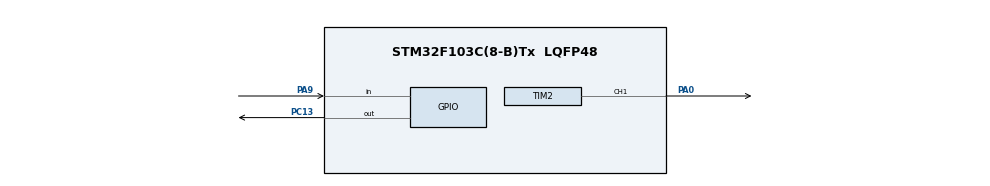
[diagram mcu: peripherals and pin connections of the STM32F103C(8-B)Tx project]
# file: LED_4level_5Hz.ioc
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Mcu.Family=STM32F1
Mcu.Name=STM32F103C(8-B)Tx
Mcu.Package=LQFP48
NVIC.PriorityGroup=NVIC_PRIORITYGROUP_4
NVIC.TIM1_UP_IRQn=true\:0\:0\:false\:false\:true\:true\:true\:true
PA0-WKUP.Signal=S_TIM2_CH1_ETR
PA13.Mode=Serial_Wire
PA13.Signal=SYS_JTMS-SWDIO
PA14.Mode=Serial_Wire
PA14.Signal=SYS_JTCK-SWCLK
PA9.GPIO_PuPd=GPIO_PULLUP
PA9.Signal=GPIO_Input
PC13-TAMPER-RTC.GPIO_ModeDefaultOutputPP=GPIO_MODE_OUTPUT_OD
PC13-TAMPER-RTC.GPIO_PuPd=GPIO_NOPULL
PC13-TAMPER-RTC.PinState=GPIO_PIN_SET
PC13-TAMPER-RTC.Signal=GPIO_Output
ProjectManager.HeapSize=0x200
ProjectManager.StackSize=0x400
ProjectManager.TargetToolchain=MDK-ARM V5.32
RCC.APB1Freq_Value=8000000
RCC.APB2Freq_Value=8000000
SH.S_TIM2_CH1_ETR.0=TIM2_CH1,PWM Generation1 CH1
TIM1.Period=99
TIM1.Prescaler=799
TIM2.Channel-PWM\ Generation1\ CH1=TIM_CHANNEL_1
TIM2.Period=999
TIM2.Prescaler=7
VP_TIM1_VS_ClockSourceINT.Mode=Internal
VP_TIM2_VS_ClockSourceINT.Mode=Internal
board=custom

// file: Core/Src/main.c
/* USER CODE BEGIN Header */
/**
  ******************************************************************************
  * @file           : main.c
  * @brief          : Main program body
  ******************************************************************************
  * @attention
  *
  * Copyright (c) 2026 STMicroelectronics.
  * All rights reserved.
  *
  * This software is licensed under terms that can be found in the LICENSE file
  * in the root directory of this software component.
  * If no LICENSE file comes with this software, it is provided AS-IS.
  *
  ******************************************************************************
  */
/* USER CODE END Header */
#include "main.h"

TIM_HandleTypeDef htim1;
TIM_HandleTypeDef htim2;

/* USER CODE BEGIN PV */
volatile uint8_t LED_long_flag = 0;//1表示长按进入呼吸灯效果
volatile uint8_t LED_short_flag = 0;//1表示短按，4种亮度循环变化
uint8_t key_state_per = 1 ;//上一次按键状态
uint8_t key_state_cur =1;//当前按键状态
uint16_t LED_ccr = 0;//LED的ccr值
int8_t LED_step = 1;//长按呼吸灯的单次改变值
uint8_t tick = 0;//每1ms一次
uint8_t mode = 1;//1为短按模式，2为长按模式
uint8_t level = 0;//亮度等级1到4
volatile uint8_t breath_flag = 0;//1为呼吸灯进行的标志
/* USER CODE END PV */

void SystemClock_Config(void);
static void MX_GPIO_Init(void);
static void MX_TIM1_Init(void);
static void MX_TIM2_Init(void);

int main(void)
{

  /* MCU Configuration--------------------------------------------------------*/

  /* Reset of all peripherals, Initializes the Flash interface and the Systick. */
  HAL_Init();

  /* Configure the system clock */
  SystemClock_Config();

  /* Initialize all configured peripherals */
  MX_GPIO_Init();
  MX_TIM1_Init();
  MX_TIM2_Init();
  /* USER CODE BEGIN 2 */
  HAL_TIM_Base_Start_IT(&htim1);//启动定时器1，并开启中断
  HAL_TIM_PWM_Start(&htim2, TIM_CHANNEL_1);//定时器2输出PWM波
  /* USER CODE END 2 */

  /* Infinite loop */
  /* USER CODE BEGIN WHILE */
  while (1)
  {
    if(LED_long_flag == 1)//出现长按标记
    {
      if(mode == 1)
      {
        mode = 2;
      }
      else if(mode == 2)
      {
        mode = 1;
      }
      LED_long_flag = 0;
    }
    if(LED_short_flag == 1 && mode == 1)//短按标志出现
    {
      if(level < 4)
      {
        level++;
      }
      else if(level >= 4)
      {
        level = 1;
      }
      LED_ccr = 250 * level;
      __HAL_TIM_SET_COMPARE(&htim2, TIM_CHANNEL_1, LED_ccr);
      LED_short_flag = 0;
    }
    if(mode == 2 && breath_flag == 1)
    {
      breath_flag = 0;
      LED_ccr += LED_step;
      if(LED_ccr >= 1000)
      {
        LED_step = -LED_step;
      }
      if(LED_ccr <= 0)
      {
        LED_step = -LED_step;
      }
      __HAL_TIM_SET_COMPARE(&htim2, TIM_CHANNEL_1, LED_ccr);

    }
    /* USER CODE END WHILE */

  }
}

void SystemClock_Config(void)
{
  RCC_OscInitTypeDef RCC_OscInitStruct = {0};
  RCC_ClkInitTypeDef RCC_ClkInitStruct = {0};

  /** Initializes the RCC Oscillators according to the specified parameters
  * in the RCC_OscInitTypeDef structure.
  */
  RCC_OscInitStruct.OscillatorType = RCC_OSCILLATORTYPE_HSI;
  RCC_OscInitStruct.HSIState = RCC_HSI_ON;
  RCC_OscInitStruct.HSICalibrationValue = RCC_HSICALIBRATION_DEFAULT;
  RCC_OscInitStruct.PLL.PLLState = RCC_PLL_NONE;
  if (HAL_RCC_OscConfig(&RCC_OscInitStruct) != HAL_OK)
  {
    Error_Handler();
  }

  /** Initializes the CPU, AHB and APB buses clocks
  */
  RCC_ClkInitStruct.ClockType = RCC_CLOCKTYPE_HCLK|RCC_CLOCKTYPE_SYSCLK
                              |RCC_CLOCKTYPE_PCLK1|RCC_CLOCKTYPE_PCLK2;
  RCC_ClkInitStruct.SYSCLKSource = RCC_SYSCLKSOURCE_HSI;
  RCC_ClkInitStruct.AHBCLKDivider = RCC_SYSCLK_DIV1;
  RCC_ClkInitStruct.APB1CLKDivider = RCC_HCLK_DIV1;
  RCC_ClkInitStruct.APB2CLKDivider = RCC_HCLK_DIV1;

  if (HAL_RCC_ClockConfig(&RCC_ClkInitStruct, FLASH_LATENCY_0) != HAL_OK)
  {
    Error_Handler();
  }
}

static void MX_TIM1_Init(void)
{

  TIM_ClockConfigTypeDef sClockSourceConfig = {0};
  TIM_MasterConfigTypeDef sMasterConfig = {0};

  htim1.Instance = TIM1;
  htim1.Init.Prescaler = 799;
  htim1.Init.CounterMode = TIM_COUNTERMODE_UP;
  htim1.Init.Period = 99;
  htim1.Init.ClockDivision = TIM_CLOCKDIVISION_DIV1;
  htim1.Init.RepetitionCounter = 0;
  htim1.Init.AutoReloadPreload = TIM_AUTORELOAD_PRELOAD_DISABLE;
  if (HAL_TIM_Base_Init(&htim1) != HAL_OK)
  {
    Error_Handler();
  }
  sClockSourceConfig.ClockSource = TIM_CLOCKSOURCE_INTERNAL;
  if (HAL_TIM_ConfigClockSource(&htim1, &sClockSourceConfig) != HAL_OK)
  {
    Error_Handler();
  }
  sMasterConfig.MasterOutputTrigger = TIM_TRGO_RESET;
  sMasterConfig.MasterSlaveMode = TIM_MASTERSLAVEMODE_DISABLE;
  if (HAL_TIMEx_MasterConfigSynchronization(&htim1, &sMasterConfig) != HAL_OK)
  {
    Error_Handler();
  }

}

static void MX_TIM2_Init(void)
{

  TIM_ClockConfigTypeDef sClockSourceConfig = {0};
  TIM_MasterConfigTypeDef sMasterConfig = {0};
  TIM_OC_InitTypeDef sConfigOC = {0};

  htim2.Instance = TIM2;
  htim2.Init.Prescaler = 7;
  htim2.Init.CounterMode = TIM_COUNTERMODE_UP;
  htim2.Init.Period = 999;
  htim2.Init.ClockDivision = TIM_CLOCKDIVISION_DIV1;
  htim2.Init.AutoReloadPreload = TIM_AUTORELOAD_PRELOAD_DISABLE;
  if (HAL_TIM_Base_Init(&htim2) != HAL_OK)
  {
    Error_Handler();
  }
  sClockSourceConfig.ClockSource = TIM_CLOCKSOURCE_INTERNAL;
  if (HAL_TIM_ConfigClockSource(&htim2, &sClockSourceConfig) != HAL_OK)
  {
    Error_Handler();
  }
  if (HAL_TIM_PWM_Init(&htim2) != HAL_OK)
  {
    Error_Handler();
  }
  sMasterConfig.MasterOutputTrigger = TIM_TRGO_RESET;
  sMasterConfig.MasterSlaveMode = TIM_MASTERSLAVEMODE_DISABLE;
  if (HAL_TIMEx_MasterConfigSynchronization(&htim2, &sMasterConfig) != HAL_OK)
  {
    Error_Handler();
  }
  sConfigOC.OCMode = TIM_OCMODE_PWM1;
  sConfigOC.Pulse = 0;
  sConfigOC.OCPolarity = TIM_OCPOLARITY_HIGH;
  sConfigOC.OCFastMode = TIM_OCFAST_DISABLE;
  if (HAL_TIM_PWM_ConfigChannel(&htim2, &sConfigOC, TIM_CHANNEL_1) != HAL_OK)
  {
    Error_Handler();
  }
  HAL_TIM_MspPostInit(&htim2);

}

static void MX_GPIO_Init(void)
{
  GPIO_InitTypeDef GPIO_InitStruct = {0};

  /* GPIO Ports Clock Enable */
  __HAL_RCC_GPIOC_CLK_ENABLE();
  __HAL_RCC_GPIOA_CLK_ENABLE();

  /*Configure GPIO pin Output Level */
  HAL_GPIO_WritePin(GPIOC, GPIO_PIN_13, GPIO_PIN_SET);

  /*Configure GPIO pin : PC13 */
  GPIO_InitStruct.Pin = GPIO_PIN_13;
  GPIO_InitStruct.Mode = GPIO_MODE_OUTPUT_OD;
  GPIO_InitStruct.Pull = GPIO_NOPULL;
  GPIO_InitStruct.Speed = GPIO_SPEED_FREQ_LOW;
  HAL_GPIO_Init(GPIOC, &GPIO_InitStruct);

  /*Configure GPIO pin : PA9 */
  GPIO_InitStruct.Pin = GPIO_PIN_9;
  GPIO_InitStruct.Mode = GPIO_MODE_INPUT;
  GPIO_InitStruct.Pull = GPIO_PULLUP;
  HAL_GPIO_Init(GPIOA, &GPIO_InitStruct);

}

/* USER CODE BEGIN 4 */
void HAL_TIM_PeriodElapsedCallback(TIM_HandleTypeDef * htim)
{
  if(htim == &htim1)//中断10ms一次
  {
    key_state_cur = HAL_GPIO_ReadPin(GPIOA, GPIO_PIN_9);
    if(key_state_cur == 0)
    {
      tick++;
      if(tick >= 100)//识别长按
      {
        LED_long_flag = 1;
        tick = 0;
      }
    }
    else
    {
     if(tick >= 2 && tick < 100)//20ms消抖，判断为短按
      {
        LED_short_flag = 1;
      }
      tick = 0;
    }
    key_state_per = key_state_cur;
    breath_flag = 1;
  }

}
/* USER CODE END 4 */

void Error_Handler(void)
{
  __disable_irq();
  while (1)
  {
  }
}
